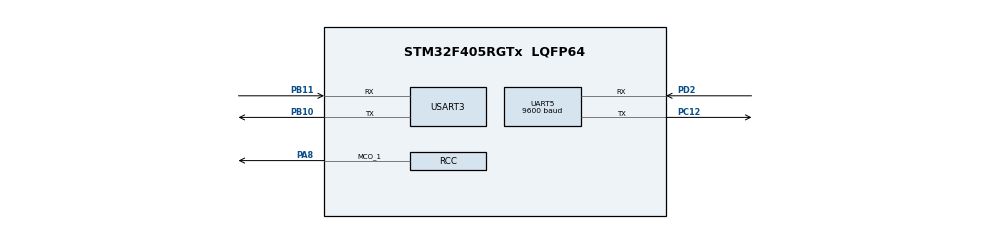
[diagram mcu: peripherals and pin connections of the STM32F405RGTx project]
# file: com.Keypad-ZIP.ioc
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Mcu.Family=STM32F4
Mcu.Name=STM32F405RGTx
Mcu.Package=LQFP64
NVIC.PriorityGroup=NVIC_PRIORITYGROUP_4
PA8.GPIO_Speed=GPIO_SPEED_FREQ_VERY_HIGH
PA8.Mode=Clock-out-1
PA8.Signal=RCC_MCO_1
PB10.Mode=Asynchronous
PB10.Signal=USART3_TX
PB11.Mode=Asynchronous
PB11.Signal=USART3_RX
PC12.Mode=Asynchronous
PC12.Signal=UART5_TX
PD2.Mode=Asynchronous
PD2.Signal=UART5_RX
PH0-OSC_IN.Mode=HSE-External-Oscillator
PH0-OSC_IN.Signal=RCC_OSC_IN
PH1-OSC_OUT.Mode=HSE-External-Oscillator
PH1-OSC_OUT.Signal=RCC_OSC_OUT
ProjectManager.HeapSize=0x200
ProjectManager.StackSize=0x400
ProjectManager.TargetToolchain=Makefile
RCC.48MHZClocksFreq_Value=84000000
RCC.AHBFreq_Value=168000000
RCC.APB1CLKDivider=RCC_HCLK_DIV4
RCC.APB1Freq_Value=42000000
RCC.APB1TimFreq_Value=84000000
RCC.APB2CLKDivider=RCC_HCLK_DIV2
RCC.APB2Freq_Value=84000000
RCC.APB2TimFreq_Value=168000000
RCC.CortexFreq_Value=168000000
RCC.HCLKFreq_Value=168000000
RCC.HSE_VALUE=8000000
RCC.HSI_VALUE=16000000
RCC.LSE_VALUE=32768
RCC.PLLM=4
RCC.PLLN=168
RCC.PLLSourceVirtual=RCC_PLLSOURCE_HSE
RCC.RCC_MCO1Source=RCC_MCO1SOURCE_PLLCLK
RCC.RCC_MCODiv1=RCC_MCODIV_5
RCC.SYSCLKFreq_VALUE=168000000
RCC.SYSCLKSource=RCC_SYSCLKSOURCE_PLLCLK
RCC.VCOOutputFreq_Value=336000000
UART5.BaudRate=9600
UART5.VirtualMode=Asynchronous
USART3.VirtualMode=VM_ASYNC
board=custom

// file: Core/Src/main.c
/* USER CODE BEGIN Header */
/**
  ******************************************************************************
  * @file           : main.c
  * @brief          : Main program body
  ******************************************************************************
  * @attention
  *
  * Copyright (c) 2024 STMicroelectronics.
  * All rights reserved.
  *
  * This software is licensed under terms that can be found in the LICENSE file
  * in the root directory of this software component.
  * If no LICENSE file comes with this software, it is provided AS-IS.
  *
  ******************************************************************************
  */
/* USER CODE END Header */
#include "main.h"

UART_HandleTypeDef huart5;
UART_HandleTypeDef huart3;

void SystemClock_Config(void);
static void MX_GPIO_Init(void);
static void MX_USART3_UART_Init(void);
static void MX_UART5_Init(void);

int main(void)
{

  /* MCU Configuration--------------------------------------------------------*/

  /* Reset of all peripherals, Initializes the Flash interface and the Systick. */
  HAL_Init();

  /* Configure the system clock */
  SystemClock_Config();

  /* Initialize all configured peripherals */
  MX_GPIO_Init();
  MX_USART3_UART_Init();
  MX_UART5_Init();

  /* Infinite loop */
  while (1)
  {

    /* USER CODE BEGIN 3 */
    HAL_UART_Transmit(&huart3, (uint8_t*)"Who's where?\n", 13, 1000);
    HAL_UART_Transmit(&huart5, (uint8_t*)"WhoIs where?\n", 13, 1000);
    HAL_Delay(1000);
    HAL_UART_Transmit(&huart3, (uint8_t*)"Hello USART3\n", 13, 1000);
    HAL_UART_Transmit(&huart5, (uint8_t*)"Hello UART5!\n", 13, 1000);
    HAL_Delay(1000);
  }
  /* USER CODE END 3 */
}

void SystemClock_Config(void)
{
  LL_FLASH_SetLatency(LL_FLASH_LATENCY_5);
  while(LL_FLASH_GetLatency()!= LL_FLASH_LATENCY_5)
  {
  }
  LL_PWR_SetRegulVoltageScaling(LL_PWR_REGU_VOLTAGE_SCALE1);
  LL_RCC_HSE_Enable();

   /* Wait till HSE is ready */
  while(LL_RCC_HSE_IsReady() != 1)
  {

  }
  LL_RCC_PLL_ConfigDomain_SYS(LL_RCC_PLLSOURCE_HSE, LL_RCC_PLLM_DIV_4, 168, LL_RCC_PLLP_DIV_2);
  LL_RCC_PLL_Enable();

   /* Wait till PLL is ready */
  while(LL_RCC_PLL_IsReady() != 1)
  {

  }
  while (LL_PWR_IsActiveFlag_VOS() == 0)
  {
  }
  LL_RCC_SetAHBPrescaler(LL_RCC_SYSCLK_DIV_1);
  LL_RCC_SetAPB1Prescaler(LL_RCC_APB1_DIV_4);
  LL_RCC_SetAPB2Prescaler(LL_RCC_APB2_DIV_2);
  LL_RCC_SetSysClkSource(LL_RCC_SYS_CLKSOURCE_PLL);

   /* Wait till System clock is ready */
  while(LL_RCC_GetSysClkSource() != LL_RCC_SYS_CLKSOURCE_STATUS_PLL)
  {

  }
  LL_SetSystemCoreClock(168000000);

   /* Update the time base */
  if (HAL_InitTick (TICK_INT_PRIORITY) != HAL_OK)
  {
    Error_Handler();
  }
  LL_RCC_ConfigMCO(LL_RCC_MCO1SOURCE_PLLCLK, LL_RCC_MCO1_DIV_5);
}

static void MX_UART5_Init(void)
{

  huart5.Instance = UART5;
  huart5.Init.BaudRate = 9600;
  huart5.Init.WordLength = UART_WORDLENGTH_8B;
  huart5.Init.StopBits = UART_STOPBITS_1;
  huart5.Init.Parity = UART_PARITY_NONE;
  huart5.Init.Mode = UART_MODE_TX_RX;
  huart5.Init.HwFlowCtl = UART_HWCONTROL_NONE;
  huart5.Init.OverSampling = UART_OVERSAMPLING_16;
  if (HAL_UART_Init(&huart5) != HAL_OK)
  {
    Error_Handler();
  }

}

static void MX_USART3_UART_Init(void)
{

  huart3.Instance = USART3;
  huart3.Init.BaudRate = 115200;
  huart3.Init.WordLength = UART_WORDLENGTH_8B;
  huart3.Init.StopBits = UART_STOPBITS_1;
  huart3.Init.Parity = UART_PARITY_NONE;
  huart3.Init.Mode = UART_MODE_TX_RX;
  huart3.Init.HwFlowCtl = UART_HWCONTROL_NONE;
  huart3.Init.OverSampling = UART_OVERSAMPLING_16;
  if (HAL_UART_Init(&huart3) != HAL_OK)
  {
    Error_Handler();
  }

}

static void MX_GPIO_Init(void)
{
  GPIO_InitTypeDef GPIO_InitStruct = {0};

  /* GPIO Ports Clock Enable */
  __HAL_RCC_GPIOH_CLK_ENABLE();
  __HAL_RCC_GPIOB_CLK_ENABLE();
  __HAL_RCC_GPIOA_CLK_ENABLE();
  __HAL_RCC_GPIOC_CLK_ENABLE();
  __HAL_RCC_GPIOD_CLK_ENABLE();

  /*Configure GPIO pin : PA8 */
  GPIO_InitStruct.Pin = GPIO_PIN_8;
  GPIO_InitStruct.Mode = GPIO_MODE_AF_PP;
  GPIO_InitStruct.Pull = GPIO_NOPULL;
  GPIO_InitStruct.Speed = GPIO_SPEED_FREQ_VERY_HIGH;
  GPIO_InitStruct.Alternate = GPIO_AF0_MCO;
  HAL_GPIO_Init(GPIOA, &GPIO_InitStruct);

}

void Error_Handler(void)
{
  __disable_irq();
  while (1)
  {
  }
}
